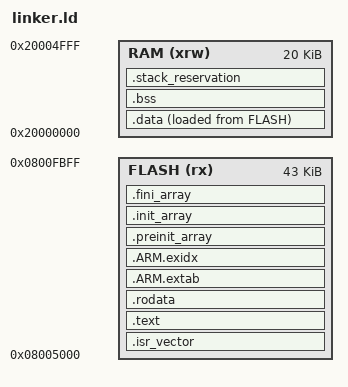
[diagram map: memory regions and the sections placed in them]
ENTRY(Reset_Handler)

_estack = ORIGIN(RAM) + LENGTH(RAM);
_Min_Stack_Size = 0x400;

MEMORY
{
  FLASH (rx)  : ORIGIN = 0x08005000, LENGTH = 0xAC00
  RAM   (xrw) : ORIGIN = 0x20000000, LENGTH = 20K
}

SECTIONS
{
  .isr_vector ORIGIN(FLASH) :
  {
    . = ALIGN(128);
    KEEP(*(.isr_vector))
    . = ALIGN(4);
  } > FLASH

  .text :
  {
    . = ALIGN(4);
    *(.text)
    *(.text*)
    *(.glue_7)
    *(.glue_7t)
    . = ALIGN(4);
    _etext = .;
  } > FLASH

  .rodata :
  {
    . = ALIGN(4);
    *(.rodata)
    *(.rodata*)
    . = ALIGN(4);
  } > FLASH

  .ARM.extab :
  {
    . = ALIGN(4);
    *(.ARM.extab* .gnu.linkonce.armextab.*)
    . = ALIGN(4);
  } > FLASH

  .ARM.exidx :
  {
    . = ALIGN(4);
    __exidx_start = .;
    *(.ARM.exidx*)
    __exidx_end = .;
    . = ALIGN(4);
  } > FLASH

  .preinit_array :
  {
    . = ALIGN(4);
    PROVIDE_HIDDEN(__preinit_array_start = .);
    KEEP(*(.preinit_array*))
    PROVIDE_HIDDEN(__preinit_array_end = .);
    . = ALIGN(4);
  } > FLASH

  .init_array :
  {
    . = ALIGN(4);
    PROVIDE_HIDDEN(__init_array_start = .);
    KEEP(*(SORT(.init_array.*)))
    KEEP(*(.init_array*))
    PROVIDE_HIDDEN(__init_array_end = .);
    . = ALIGN(4);
  } > FLASH

  .fini_array :
  {
    . = ALIGN(4);
    PROVIDE_HIDDEN(__fini_array_start = .);
    KEEP(*(SORT(.fini_array.*)))
    KEEP(*(.fini_array*))
    PROVIDE_HIDDEN(__fini_array_end = .);
    . = ALIGN(4);
  } > FLASH

  _sidata = LOADADDR(.data);

  .data :
  {
    . = ALIGN(4);
    _sdata = .;
    *(.data)
    *(.data*)
    . = ALIGN(4);
    _edata = .;
  } > RAM AT > FLASH

  .bss (NOLOAD) :
  {
    . = ALIGN(4);
    _sbss = .;
    __bss_start__ = .;
    *(.bss)
    *(.bss*)
    *(COMMON)
    . = ALIGN(4);
    _ebss = .;
    __bss_end__ = .;
  } > RAM

  .stack_reservation (NOLOAD) :
  {
    . = ALIGN(8);
    _end = .;
    end = .;
    . = . + _Min_Stack_Size;
    . = ALIGN(8);
    _stack_reservation_end = .;
  } > RAM

  /DISCARD/ :
  {
    *(.comment)
    *(.note*)
  }

  .ARM.attributes 0 : { *(.ARM.attributes) }
}

ASSERT(ADDR(.isr_vector) == 0x08005000,
       "application vector table is not at 0x08005000")
ASSERT(ORIGIN(FLASH) + LENGTH(FLASH) == 0x0800FC00,
       "application FLASH region overlaps the metadata page")
ASSERT(_stack_reservation_end <= ORIGIN(RAM) + LENGTH(RAM),
       "application RAM plus reserved stack exceeds 20 KiB")
